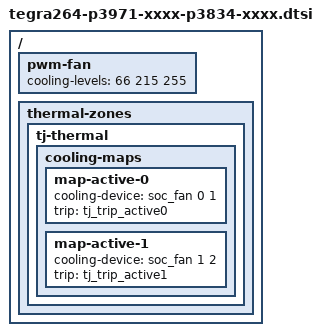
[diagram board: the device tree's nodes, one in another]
// SPDX-License-Identifier: GPL-2.0-only
// SPDX-FileCopyrightText: Copyright (c) 2024, NVIDIA CORPORATION & AFFILIATES.  All rights reserved.

#include "nv-soc/tegra264-soc-thermal-slowdown.dtsi"

/ {
	pwm-fan {
		cooling-levels = <66 215 255>;
	};

	thermal-zones {
		tj-thermal {
			cooling-maps {
				map-active-0 {
					cooling-device = <&soc_fan 0 1>;
					trip = <&tj_trip_active0>;
				};

				map-active-1 {
					cooling-device = <&soc_fan 1 2>;
					trip = <&tj_trip_active1>;
				};
			};
		};
	};
};
